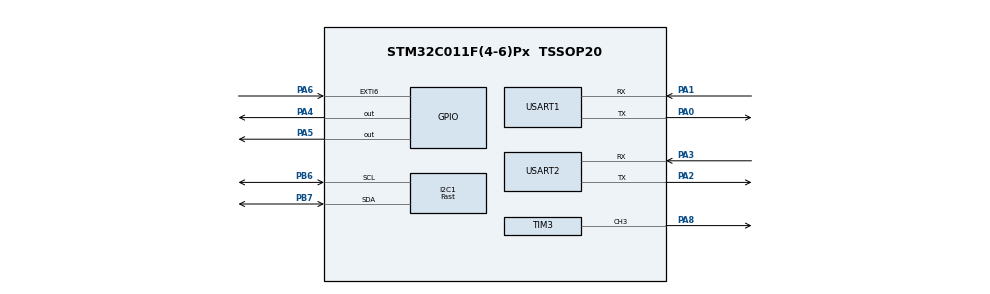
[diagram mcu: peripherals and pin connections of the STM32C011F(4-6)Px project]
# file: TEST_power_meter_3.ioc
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Dma.Request0=USART1_TX
Dma.Request1=USART2_TX
Dma.USART1_TX.0.Direction=DMA_MEMORY_TO_PERIPH
Dma.USART1_TX.0.EventEnable=DISABLE
Dma.USART1_TX.0.Instance=DMA1_Channel1
Dma.USART1_TX.0.MemDataAlignment=DMA_MDATAALIGN_BYTE
Dma.USART1_TX.0.MemInc=DMA_MINC_ENABLE
Dma.USART1_TX.0.Mode=DMA_NORMAL
Dma.USART1_TX.0.PeriphDataAlignment=DMA_PDATAALIGN_BYTE
Dma.USART1_TX.0.PeriphInc=DMA_PINC_DISABLE
Dma.USART1_TX.0.Polarity=HAL_DMAMUX_REQ_GEN_RISING
Dma.USART1_TX.0.Priority=DMA_PRIORITY_LOW
Dma.USART1_TX.0.RequestNumber=1
Dma.USART1_TX.0.SignalID=NONE
Dma.USART1_TX.0.SyncEnable=DISABLE
Dma.USART1_TX.0.SyncPolarity=HAL_DMAMUX_SYNC_NO_EVENT
Dma.USART1_TX.0.SyncRequestNumber=1
Dma.USART1_TX.0.SyncSignalID=NONE
Dma.USART2_TX.1.Direction=DMA_MEMORY_TO_PERIPH
Dma.USART2_TX.1.EventEnable=DISABLE
Dma.USART2_TX.1.Instance=DMA1_Channel2
Dma.USART2_TX.1.MemDataAlignment=DMA_MDATAALIGN_BYTE
Dma.USART2_TX.1.MemInc=DMA_MINC_ENABLE
Dma.USART2_TX.1.Mode=DMA_NORMAL
Dma.USART2_TX.1.PeriphDataAlignment=DMA_PDATAALIGN_BYTE
Dma.USART2_TX.1.PeriphInc=DMA_PINC_DISABLE
Dma.USART2_TX.1.Polarity=HAL_DMAMUX_REQ_GEN_RISING
Dma.USART2_TX.1.Priority=DMA_PRIORITY_LOW
Dma.USART2_TX.1.RequestNumber=1
Dma.USART2_TX.1.SignalID=NONE
Dma.USART2_TX.1.SyncEnable=DISABLE
Dma.USART2_TX.1.SyncPolarity=HAL_DMAMUX_SYNC_NO_EVENT
Dma.USART2_TX.1.SyncRequestNumber=1
Dma.USART2_TX.1.SyncSignalID=NONE
I2C1.I2C_Speed_Mode=I2C_Fast
I2C1.Timing=0x0090194B
Mcu.Family=STM32C0
Mcu.Name=STM32C011F(4-6)Px
Mcu.Package=TSSOP20
NVIC.DMA1_Channel1_IRQn=true\:0\:0\:false\:false\:true\:false\:true\:true
NVIC.DMA1_Channel2_3_IRQn=true\:0\:0\:false\:false\:true\:false\:true\:true
NVIC.EXTI4_15_IRQn=true\:0\:0\:false\:false\:true\:true\:true\:true
NVIC.I2C1_IRQn=true\:0\:0\:false\:false\:true\:true\:true\:true
NVIC.USART1_IRQn=true\:0\:0\:false\:false\:true\:true\:true\:true
NVIC.USART2_IRQn=true\:0\:0\:false\:false\:true\:true\:true\:true
PA0.Mode=Asynchronous
PA0.Signal=USART1_TX
PA1.Mode=Asynchronous
PA1.Signal=USART1_RX
PA13.Mode=Serial_Wire
PA13.Signal=DEBUG_SWDIO
PA14-BOOT0.Mode=Serial_Wire
PA14-BOOT0.Signal=DEBUG_SWCLK
PA2.Mode=Asynchronous
PA2.Signal=USART2_TX
PA3.Mode=Asynchronous
PA3.Signal=USART2_RX
PA4.GPIO_PuPd=GPIO_PULLDOWN
PA4.Signal=GPIO_Output
PA5.GPIO_PuPd=GPIO_PULLDOWN
PA5.Signal=GPIO_Output
PA6.Signal=GPXTI6
PA8.Signal=S_TIM3_CH3
PB6.Mode=I2C
PB6.Signal=I2C1_SCL
PB7.Mode=I2C
PB7.Signal=I2C1_SDA
ProjectManager.HeapSize=0x200
ProjectManager.StackSize=0x800
ProjectManager.TargetToolchain=MDK-ARM V5.39
RCC.ADCFreq_Value=48000000
RCC.AHBFreq_Value=48000000
RCC.CortexFreq_Value=48000000
RCC.EXTERNAL_CLOCK_VALUE=12288000
RCC.HCLKFreq_Value=48000000
RCC.HSE_VALUE=8000000
RCC.HSISYSCLKDivider=RCC_HSI_DIV1
RCC.HSI_VALUE=48000000
RCC.LSE_VALUE=32768
RCC.SYSCLKFreq_VALUE=48000000
SH.S_TIM3_CH3.0=TIM3_CH3,PWM Generation3 CH3
TIM3.Channel-PWM\ Generation3\ CH3=TIM_CHANNEL_3
USART1.VirtualMode-Asynchronous=VM_ASYNC
USART2.SwapParam=ADVFEATURE_SWAP_ENABLE
USART2.VirtualMode-Asynchronous=VM_ASYNC
board=custom

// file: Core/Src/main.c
/* USER CODE BEGIN Header */
/**
  ******************************************************************************
  * @file           : main.c
  * @brief          : Main program body
  ******************************************************************************
  * @attention
  *
  * Copyright (c) 2026 STMicroelectronics.
  * All rights reserved.
  *
  * This software is licensed under terms that can be found in the LICENSE file
  * in the root directory of this software component.
  * If no LICENSE file comes with this software, it is provided AS-IS.
  *
  ******************************************************************************
  */
/* USER CODE END Header */
#include "main.h"
#include "i2c.h"
#include "tim.h"
#include "usart.h"
#include "gpio.h"

/* USER CODE BEGIN Includes */
#include "app.h"        /* 应用层入口: App_Init / App_Task */
/* USER CODE END Includes */

void SystemClock_Config(void);

int main(void)
{

  /* MCU Configuration--------------------------------------------------------*/

  /* Reset of all peripherals, Initializes the Flash interface and the Systick. */
  HAL_Init();

  /* Configure the system clock */
  SystemClock_Config();

  /* Initialize all configured peripherals */
  MX_GPIO_Init();
  MX_I2C1_Init();
  MX_TIM3_Init();
  MX_USART1_UART_Init();
  MX_USART2_UART_Init();
  /* USER CODE BEGIN 2 */
  App_Init();   /* 应用初始化 */
  /* USER CODE END 2 */

  /* Infinite loop */
  while (1)
  {

    /* USER CODE BEGIN 3 */
    /* [版本 2026-10-08 17:32]
       界面为 KK_UI(KK_OLED 显示); 本板只装一个键 PA6:
       短按 = 下一个/返回, 长按 = 确认进入, 自定义页短按 = 返回;
       帧单位 10mV/10mA/0.5W, USART1 二进制 115200@500Hz, USART2 文本 115200@10Hz;
       INA228 连读带超时保护(10ms), 功率扣零点偏移, 电流峰值取绝对值 */
    App_Task();   /* 应用主循环 */
  }
  /* USER CODE END 3 */
}

void SystemClock_Config(void)
{
  RCC_OscInitTypeDef RCC_OscInitStruct = {0};
  RCC_ClkInitTypeDef RCC_ClkInitStruct = {0};

  __HAL_FLASH_SET_LATENCY(FLASH_LATENCY_1);

  /** Initializes the RCC Oscillators according to the specified parameters
  * in the RCC_OscInitTypeDef structure.
  */
  RCC_OscInitStruct.OscillatorType = RCC_OSCILLATORTYPE_HSI;
  RCC_OscInitStruct.HSIState = RCC_HSI_ON;
  RCC_OscInitStruct.HSIDiv = RCC_HSI_DIV1;
  RCC_OscInitStruct.HSICalibrationValue = RCC_HSICALIBRATION_DEFAULT;
  if (HAL_RCC_OscConfig(&RCC_OscInitStruct) != HAL_OK)
  {
    Error_Handler();
  }

  /** Initializes the CPU, AHB and APB buses clocks
  */
  RCC_ClkInitStruct.ClockType = RCC_CLOCKTYPE_HCLK|RCC_CLOCKTYPE_SYSCLK
                              |RCC_CLOCKTYPE_PCLK1;
  RCC_ClkInitStruct.SYSCLKSource = RCC_SYSCLKSOURCE_HSI;
  RCC_ClkInitStruct.SYSCLKDivider = RCC_SYSCLK_DIV1;
  RCC_ClkInitStruct.AHBCLKDivider = RCC_HCLK_DIV1;
  RCC_ClkInitStruct.APB1CLKDivider = RCC_APB1_DIV1;

  if (HAL_RCC_ClockConfig(&RCC_ClkInitStruct, FLASH_LATENCY_1) != HAL_OK)
  {
    Error_Handler();
  }
}

void Error_Handler(void)
{
  __disable_irq();
  while (1)
  {
  }
}
